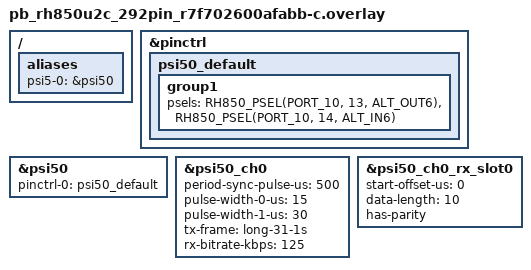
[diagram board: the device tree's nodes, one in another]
/*
 * Copyright (c) 2026 Renesas Electronics Corporation
 *
 * SPDX-License-Identifier: Apache-2.0
 */

/ {
	aliases {
		psi5-0 = &psi50;
	};
};

/* PSI50: P10_13 = TX, P10_14 = RX on U2C 292-pin. */
&pinctrl {
	psi50_default: psi50_default {
		group1 {
			psels = <RH850_PSEL(PORT_10, 13, ALT_OUT6)>,
				<RH850_PSEL(PORT_10, 14, ALT_IN6)>;
		};
	};
};

&psi50 {
	pinctrl-0 = <&psi50_default>;
	pinctrl-names = "default";
	status = "okay";
};

/*
 * PSI5-P synchronous mode. tx-frame follows the upstream NXP psi5_api overlay:
 * Long frame (FRMFORMAT = 010, 16-bit TXDATA) so test_send_* data 0x1234 fits.
 */
&psi50_ch0 {
	period-sync-pulse-us = <500>;
	pulse-width-0-us = <15>;
	pulse-width-1-us = <30>;
	tx-frame = "long-31-1s";
	rx-bitrate-kbps = <125>;
	status = "okay";
};

&psi50_ch0_rx_slot0 {
	start-offset-us = <0>;
	data-length = <10>;
	has-parity;
	status = "okay";
};
